AUTOSAR XML (schema 4-2-2)
package /AUTOSAR_WdgM
  data type mapping set WdgM_Type_Map: mode-request-type-map{implementation-data-type=uint8, mode-group=WdgM_Mode}
  mode declaration group WdgM_Mode: category=EXPLICIT_ORDER, initial-mode=SUPERVISION_OK, on-transition-value=255
    5 x mode:
      SUPERVISION_OK: value=0
      SUPERVISION_FAILED: value=1
      SUPERVISION_EXPIRED: value=2
      SUPERVISION_STOPPED: value=3
      SUPERVISION_DEACTIVATED: value=4
  client server interface WdgM_LocalSupervision: is-service=true
    operation CheckpointReached: possible-error=[E_NOT_OK, E_OK]
    error E_OK: error-code=0
    error E_NOT_OK: error-code=1
  client server interface WdgM_LocalSupervisionStatus: is-service=true
    operation GetLocalStatus: possible-error=[E_NOT_OK, E_OK]
      arg Status: type=WdgM_LocalStatusType, direction=OUT
    error E_OK: error-code=0
    error E_NOT_OK: error-code=1
  client server interface WdgM_GlobalSupervision: is-service=true
    5 x operation:
      GetFirstExpiredSEID: possible-error=[E_NOT_OK, E_OK]
        arg SEID: type=WdgM_SupervisedEntityIdType, direction=OUT
      GetGlobalStatus: possible-error=[E_NOT_OK, E_OK]
        arg Status: type=WdgM_GlobalStatusType, direction=OUT
      GetMode: possible-error=[E_NOT_OK, E_OK]
        arg Mode: type=WdgM_ModeType, direction=OUT
      PerformReset
      SetMode: possible-error=[E_NOT_OK, E_OK]
        arg Mode: type=WdgM_ModeType, direction=IN
    error E_OK: error-code=0
    error E_NOT_OK: error-code=1
  mode switch interface WdgM_LocalMode: is-service=true
    mode group currentMode: type=WdgM_Mode
  mode switch interface WdgM_GlobalMode: is-service=true
    mode group currentMode: type=WdgM_Mode
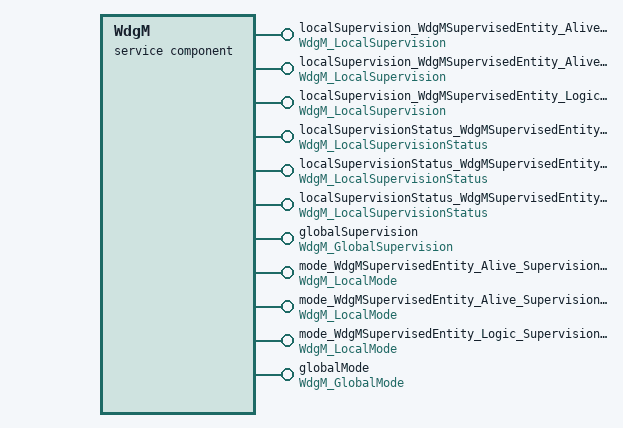
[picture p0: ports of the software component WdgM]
  service sw component type WdgM
    21 x provide port:
      localSupervision_WdgMSupervisedEntity_Alive_Supervision_CPU{1..3}_WdgMCheckpoint_Alive_Supervision_CPU{1..3}: server-com-spec{operation=CheckpointReached, queue-length=1}, provided-interface=WdgM_LocalSupervision
      localSupervision_WdgMSupervisedEntity_Alive_Supervision_Entity1_WdgMCheckpoint_Alive_Supervision_Entity1: server-com-spec{operation=CheckpointReached, queue-length=1}, provided-interface=WdgM_LocalSupervision
      localSupervision_WdgMSupervisedEntity_Logic_Supervision_Entity1_WdgMCheckpoint_{0..4}: server-com-spec{operation=CheckpointReached, queue-length=1}, provided-interface=WdgM_LocalSupervision
      localSupervisionStatus_WdgMSupervisedEntity_Alive_Supervision_CPU{1..3}: server-com-spec{operation=GetLocalStatus, queue-length=1}, provided-interface=WdgM_LocalSupervisionStatus
      localSupervisionStatus_WdgMSupervisedEntity_Alive_Supervision_Entity1: server-com-spec{operation=GetLocalStatus, queue-length=1}, provided-interface=WdgM_LocalSupervisionStatus
      localSupervisionStatus_WdgMSupervisedEntity_Logic_Supervision_Entity1: server-com-spec{operation=GetLocalStatus, queue-length=1}, provided-interface=WdgM_LocalSupervisionStatus
      globalSupervision: provided-interface=WdgM_GlobalSupervision
        provided-com-specs:
          operation=GetFirstExpiredSEID, queue-length=1
          operation=GetGlobalStatus, queue-length=1
          operation=GetMode, queue-length=1
          operation=PerformReset, queue-length=1
          operation=SetMode, queue-length=1
      mode_WdgMSupervisedEntity_Alive_Supervision_CPU{1..3}: mode-switch-sender-com-spec{mode-group=currentMode, mode-switched-ack=timeout=1.0, queue-length=1}, provided-interface=WdgM_LocalMode
      mode_WdgMSupervisedEntity_Alive_Supervision_Entity1: mode-switch-sender-com-spec{mode-group=currentMode, mode-switched-ack=timeout=1.0, queue-length=1}, provided-interface=WdgM_LocalMode
      mode_WdgMSupervisedEntity_Logic_Supervision_Entity1: mode-switch-sender-com-spec{mode-group=currentMode, mode-switched-ack=timeout=1.0, queue-length=1}, provided-interface=WdgM_LocalMode
      globalMode: mode-switch-sender-com-spec{mode-group=currentMode, mode-switched-ack=timeout=1.0, queue-length=1}, provided-interface=WdgM_GlobalMode
    behavior WdgM_InternalBehaviour: data-type-mapping=WdgM_Type_Map
      19 x operation invoked event:
        OIE_CheckpointReached_WdgMSupervisedEntity_Alive_Supervision_CPU{1..3}_WdgMCheckpoint_Alive_Supervision_CPU{1..3}: start-on-event=CheckpointReached, operation=localSupervision_WdgMSupervisedEntity_Alive_Supervision_CPU{1..3}_WdgMCheckpoint_Alive_Supervision_CPU{1..3}.CheckpointReached
        OIE_CheckpointReached_WdgMSupervisedEntity_Alive_Supervision_Entity1_WdgMCheckpoint_Alive_Supervision_Entity1: start-on-event=CheckpointReached, operation=localSupervision_WdgMSupervisedEntity_Alive_Supervision_Entity1_WdgMCheckpoint_Alive_Supervision_Entity1.CheckpointReached
        OIE_CheckpointReached_WdgMSupervisedEntity_Logic_Supervision_Entity1_WdgMCheckpoint_{0..4}: start-on-event=CheckpointReached, operation=localSupervision_WdgMSupervisedEntity_Logic_Supervision_Entity1_WdgMCheckpoint_{0..4}.CheckpointReached
        OIE_GetLocalStatus_WdgMSupervisedEntity_Alive_Supervision_CPU{1..3}: start-on-event=GetLocalStatus, operation=localSupervisionStatus_WdgMSupervisedEntity_Alive_Supervision_CPU{1..3}.GetLocalStatus
        OIE_GetLocalStatus_WdgMSupervisedEntity_Alive_Supervision_Entity1: start-on-event=GetLocalStatus, operation=localSupervisionStatus_WdgMSupervisedEntity_Alive_Supervision_Entity1.GetLocalStatus
        OIE_GetLocalStatus_WdgMSupervisedEntity_Logic_Supervision_Entity1: start-on-event=GetLocalStatus, operation=localSupervisionStatus_WdgMSupervisedEntity_Logic_Supervision_Entity1.GetLocalStatus
        OIE_GetFirstExpiredSEID: start-on-event=GetFirstExpiredSEID, operation=globalSupervision.GetFirstExpiredSEID
        OIE_GetGlobalStatus: start-on-event=GetGlobalStatus, operation=globalSupervision.GetGlobalStatus
        OIE_GetMode: start-on-event=GetMode, operation=globalSupervision.GetMode
        OIE_PerformReset: start-on-event=PerformReset, operation=globalSupervision.PerformReset
        OIE_SetMode: start-on-event=SetMode, operation=globalSupervision.SetMode
      port-api-options:
        {enable-take-address=false, indirect-api=false, port-arg-values=[{value=0, value-type=WdgM_SupervisedEntityIdType}, {value=0, value-type=WdgM_CheckpointIdType}], port=localSupervision_WdgMSupervisedEntity_Alive_Supervision_CPU1_WdgMCheckpoint_Alive_Supervision_CPU1}
        {enable-take-address=false, indirect-api=false, port-arg-values=[{value=1, value-type=WdgM_SupervisedEntityIdType}, {value=0, value-type=WdgM_CheckpointIdType}], port=localSupervision_WdgMSupervisedEntity_Alive_Supervision_CPU2_WdgMCheckpoint_Alive_Supervision_CPU2}
        {enable-take-address=false, indirect-api=false, port-arg-values=[{value=2, value-type=WdgM_SupervisedEntityIdType}, {value=0, value-type=WdgM_CheckpointIdType}], port=localSupervision_WdgMSupervisedEntity_Alive_Supervision_CPU3_WdgMCheckpoint_Alive_Supervision_CPU3}
        {enable-take-address=false, indirect-api=false, port-arg-values=[{value=3, value-type=WdgM_SupervisedEntityIdType}, {value=0, value-type=WdgM_CheckpointIdType}], port=localSupervision_WdgMSupervisedEntity_Alive_Supervision_Entity1_WdgMCheckpoint_Alive_Supervision_Entity1}
        {enable-take-address=false, indirect-api=false, port-arg-values=[{value=4, value-type=WdgM_SupervisedEntityIdType}, {value={0..4}, value-type=WdgM_CheckpointIdType}], port=localSupervision_WdgMSupervisedEntity_Logic_Supervision_Entity1_WdgMCheckpoint_{0..4}}
        {enable-take-address=false, indirect-api=false, port-defined-argument-value{value=0, value-type=WdgM_SupervisedEntityIdType}, port=localSupervisionStatus_WdgMSupervisedEntity_Alive_Supervision_CPU1}
        {enable-take-address=false, indirect-api=false, port-defined-argument-value{value=1, value-type=WdgM_SupervisedEntityIdType}, port=localSupervisionStatus_WdgMSupervisedEntity_Alive_Supervision_CPU2}
        {enable-take-address=false, indirect-api=false, port-defined-argument-value{value=2, value-type=WdgM_SupervisedEntityIdType}, port=localSupervisionStatus_WdgMSupervisedEntity_Alive_Supervision_CPU3}
        {enable-take-address=false, indirect-api=false, port-defined-argument-value{value=3, value-type=WdgM_SupervisedEntityIdType}, port=localSupervisionStatus_WdgMSupervisedEntity_Alive_Supervision_Entity1}
        {enable-take-address=false, indirect-api=false, port-defined-argument-value{value=4, value-type=WdgM_SupervisedEntityIdType}, port=localSupervisionStatus_WdgMSupervisedEntity_Logic_Supervision_Entity1}
        enable-take-address=false, indirect-api=false, port=globalSupervision
        indirect-api=true, port=mode_WdgMSupervisedEntity_Alive_Supervision_CPU{1..3}
        indirect-api=true, port=mode_WdgMSupervisedEntity_Alive_Supervision_Entity1
        indirect-api=true, port=mode_WdgMSupervisedEntity_Logic_Supervision_Entity1
        enable-take-address=true, indirect-api=false, port=globalMode
      8 x runnable:
        CheckpointReached: sw-addr-method=CODE_FAST, arguments=[symbol=SEID, symbol=CheckpointID], can-be-invoked-concurrently=true, symbol=WdgM_CheckpointReached
        GetLocalStatus: sw-addr-method=CODE_FAST, arguments=[symbol=SEID, symbol=Status], can-be-invoked-concurrently=true, symbol=WdgM_GetLocalStatus
        GetFirstExpiredSEID: sw-addr-method=CODE_SLOW, runnable-entity-argument=symbol=SEID, can-be-invoked-concurrently=true, symbol=WdgM_GetFirstExpiredSEID
        GetGlobalStatus: sw-addr-method=CODE_FAST, runnable-entity-argument=symbol=Status, can-be-invoked-concurrently=true, symbol=WdgM_GetGlobalStatus
        GetMode: sw-addr-method=CODE_FAST, runnable-entity-argument=symbol=Mode, can-be-invoked-concurrently=true, symbol=WdgM_GetMode
        PerformReset: sw-addr-method=CODE_FAST, can-be-invoked-concurrently=true, symbol=WdgM_PerformReset
        SetMode: sw-addr-method=CODE_FAST, runnable-entity-argument=symbol=Mode, can-be-invoked-concurrently=true, symbol=WdgM_SetMode
        MainFunction: symbol=WdgM_MainFunction
          6 x mode switch point:
            msp_WdgM_LocalMode_WdgMSupervisedEntity_Alive_Supervision_CPU{1..3}: mode-group=mode_WdgMSupervisedEntity_Alive_Supervision_CPU{1..3}.currentMode
            msp_WdgM_LocalMode_WdgMSupervisedEntity_Alive_Supervision_Entity1: mode-group=mode_WdgMSupervisedEntity_Alive_Supervision_Entity1.currentMode
            msp_WdgM_LocalMode_WdgMSupervisedEntity_Logic_Supervision_Entity1: mode-group=mode_WdgMSupervisedEntity_Logic_Supervision_Entity1.currentMode
            msp_WdgM_GlobalMode: mode-group=globalMode.currentMode
package /SwcImplementations
  swc implementation WdgM: programming-language=C, sw-version=8.1.0, vendor-id=6, behavior=WdgM_InternalBehaviour
    code-descriptors:
      code CodeDescriptor: artifact-descriptors=autosar-engineering-object={short-label=ArEngObj, category=SWSRC}
